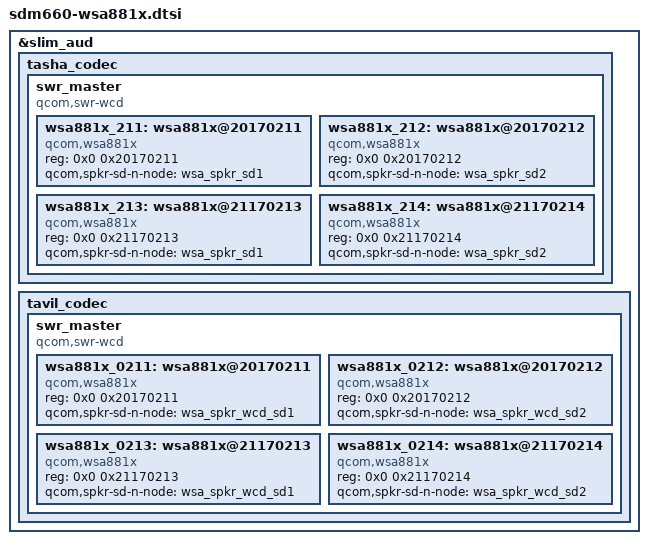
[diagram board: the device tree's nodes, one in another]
#include "sdm660-wcd.dtsi"

&slim_aud {
	tasha_codec {
		swr_master {
			compatible = "qcom,swr-wcd";
			#address-cells = <2>;
			#size-cells = <0>;

			wsa881x_211: wsa881x@20170211 {
				compatible = "qcom,wsa881x";
				reg = <0x0 0x20170211>;
				qcom,spkr-sd-n-node = <&wsa_spkr_sd1>;
			};

			wsa881x_212: wsa881x@20170212 {
				compatible = "qcom,wsa881x";
				reg = <0x0 0x20170212>;
				qcom,spkr-sd-n-node = <&wsa_spkr_sd2>;
			};

			wsa881x_213: wsa881x@21170213 {
				compatible = "qcom,wsa881x";
				reg = <0x0 0x21170213>;
				qcom,spkr-sd-n-node = <&wsa_spkr_sd1>;
			};

			wsa881x_214: wsa881x@21170214 {
				compatible = "qcom,wsa881x";
				reg = <0x0 0x21170214>;
				qcom,spkr-sd-n-node = <&wsa_spkr_sd2>;
			};
		};
	};

	tavil_codec {
		swr_master {
			compatible = "qcom,swr-wcd";
			#address-cells = <2>;
			#size-cells = <0>;

			wsa881x_0211: wsa881x@20170211 {
				compatible = "qcom,wsa881x";
				reg = <0x0 0x20170211>;
				qcom,spkr-sd-n-node = <&wsa_spkr_wcd_sd1>;
			};

			wsa881x_0212: wsa881x@20170212 {
				compatible = "qcom,wsa881x";
				reg = <0x0 0x20170212>;
				qcom,spkr-sd-n-node = <&wsa_spkr_wcd_sd2>;
			};

			wsa881x_0213: wsa881x@21170213 {
				compatible = "qcom,wsa881x";
				reg = <0x0 0x21170213>;
				qcom,spkr-sd-n-node = <&wsa_spkr_wcd_sd1>;
			};

			wsa881x_0214: wsa881x@21170214 {
				compatible = "qcom,wsa881x";
				reg = <0x0 0x21170214>;
				qcom,spkr-sd-n-node = <&wsa_spkr_wcd_sd2>;
			};
		};
	};
};
